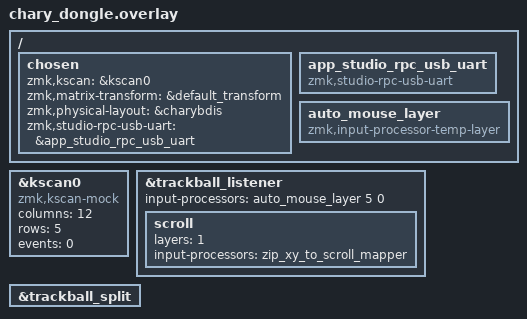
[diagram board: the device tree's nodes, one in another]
/*
 * Copyright (c) 2024 Junie
 * SPDX-License-Identifier: MIT
 */

#include "chary.dtsi"
#include <input/processors.dtsi>

/ {
    chosen {
        zmk,kscan = &kscan0;
        zmk,matrix-transform = &default_transform;
        zmk,physical-layout = &charybdis;
        zmk,studio-rpc-usb-uart = &app_studio_rpc_usb_uart;
    };

    app_studio_rpc_usb_uart: app_studio_rpc_usb_uart {
        compatible = "zmk,studio-rpc-usb-uart";
    };
};

&kscan0 {
    compatible = "zmk,kscan-mock";
    columns = <12>;
    rows = <5>;
    events = <0>;
};

&trackball_listener {
    status = "okay";
    input-processors = <&auto_mouse_layer 5 0>;

    scroll {
        layers = <1>;
        input-processors = <&zip_xy_to_scroll_mapper>;
    };
};

&trackball_split {
    status = "okay";
};

/ {
    auto_mouse_layer: auto_mouse_layer {
        compatible = "zmk,input-processor-temp-layer";
        #input-processor-cells = <2>;
    };
};
